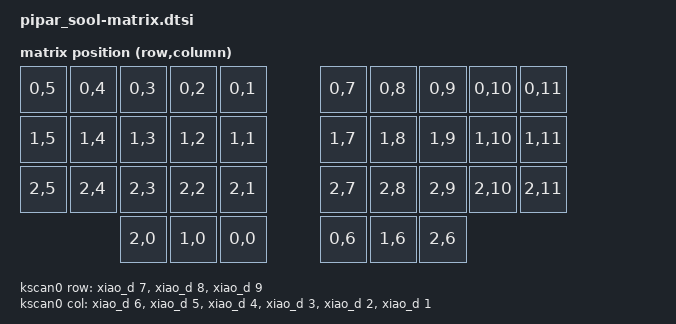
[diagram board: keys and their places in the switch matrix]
#include <dt-bindings/zmk/matrix_transform.h>
#include "pipar_sool-layouts.dtsi"

&physical_layout0 {
    transform = <&default_transform>;
};

/ {
    chosen {
        zmk,kscan = &kscan0;
        zmk,physical-layout = &physical_layout0;
    };

    default_transform: keymap_transform_0 {
        compatible = "zmk,matrix-transform";
        columns = <12>;
        rows = <3>;
                                    
        map = <
            RC(0,5)  RC(0,4)  RC(0,3)  RC(0,2)  RC(0,1)  RC(0,7)  RC(0,8)   RC(0,9)  RC(0,10)  RC(0,11)
            RC(1,5)  RC(1,4)  RC(1,3)  RC(1,2)  RC(1,1)  RC(1,7)  RC(1,8)   RC(1,9)  RC(1,10)  RC(1,11) 
            RC(2,5)  RC(2,4)  RC(2,3)  RC(2,2)  RC(2,1)  RC(2,7)  RC(2,8)   RC(2,9)  RC(2,10)  RC(2,11) 
                              RC(2,0)  RC(1,0)  RC(0,0)  RC(0,6)  RC(1,6)   RC(2,6)
        >;

    };

    kscan0: kscan_0 {
        compatible = "zmk,kscan-gpio-matrix";
        diode-direction = "col2row";
        wakeup-source;

        row-gpios
            = <&xiao_d 7 (GPIO_ACTIVE_HIGH | GPIO_PULL_DOWN)>
            , <&xiao_d 8 (GPIO_ACTIVE_HIGH | GPIO_PULL_DOWN)>
            , <&xiao_d 9 (GPIO_ACTIVE_HIGH | GPIO_PULL_DOWN)>
            ;
        
        col-gpios
            = <&xiao_d 6 GPIO_ACTIVE_HIGH>
            , <&xiao_d 5 GPIO_ACTIVE_HIGH>
            , <&xiao_d 4 GPIO_ACTIVE_HIGH>
            , <&xiao_d 3 GPIO_ACTIVE_HIGH>
            , <&xiao_d 2 GPIO_ACTIVE_HIGH>
            , <&xiao_d 1 GPIO_ACTIVE_HIGH>
            ;
    };
};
